VERSION ""

NS_ :

BS_:

BU_: IZZE_Brake_IR_4D3

BO_ 1239 IZZE_Brake_IR_4D3_Status: 8 IZZE_Brake_IR_4D3
 SG_ IZZE_Brake_IR_4D3_Internal_Temp : 7|16@0+ (0.1,-100) [0|65535] "C" Vector__XXX

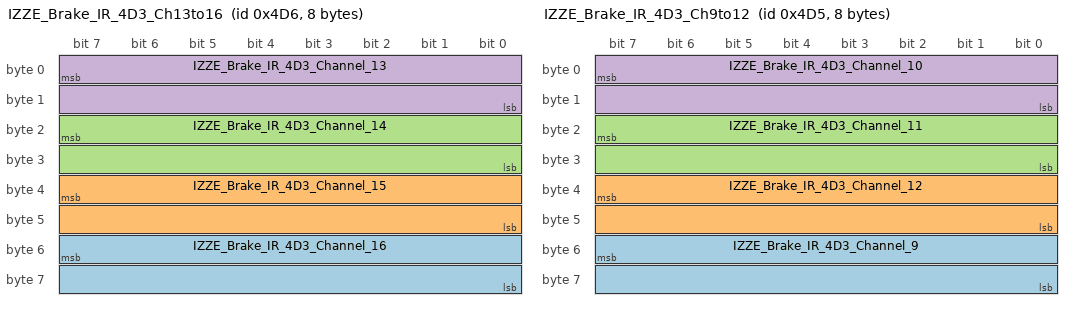
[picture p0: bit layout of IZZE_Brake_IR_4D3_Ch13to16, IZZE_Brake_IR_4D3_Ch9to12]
BO_ 1238 IZZE_Brake_IR_4D3_Ch13to16: 8 IZZE_Brake_IR_4D3
 SG_ IZZE_Brake_IR_4D3_Channel_16 : 55|16@0+ (0.1,-100) [0|65535] "C" Vector__XXX
 SG_ IZZE_Brake_IR_4D3_Channel_15 : 39|16@0+ (0.1,-100) [0|65535] "C" Vector__XXX
 SG_ IZZE_Brake_IR_4D3_Channel_14 : 23|16@0+ (0.1,-100) [0|65535] "C" Vector__XXX
 SG_ IZZE_Brake_IR_4D3_Channel_13 : 7|16@0+ (0.1,-100) [0|65535] "C" Vector__XXX

BO_ 1237 IZZE_Brake_IR_4D3_Ch9to12: 8 IZZE_Brake_IR_4D3
 SG_ IZZE_Brake_IR_4D3_Channel_9 : 55|16@0+ (0.1,-100) [0|65535] "C" Vector__XXX
 SG_ IZZE_Brake_IR_4D3_Channel_12 : 39|16@0+ (0.1,-100) [0|65535] "C" Vector__XXX
 SG_ IZZE_Brake_IR_4D3_Channel_11 : 23|16@0+ (0.1,-100) [0|65535] "C" Vector__XXX
 SG_ IZZE_Brake_IR_4D3_Channel_10 : 7|16@0+ (0.1,-100) [0|65535] "C" Vector__XXX

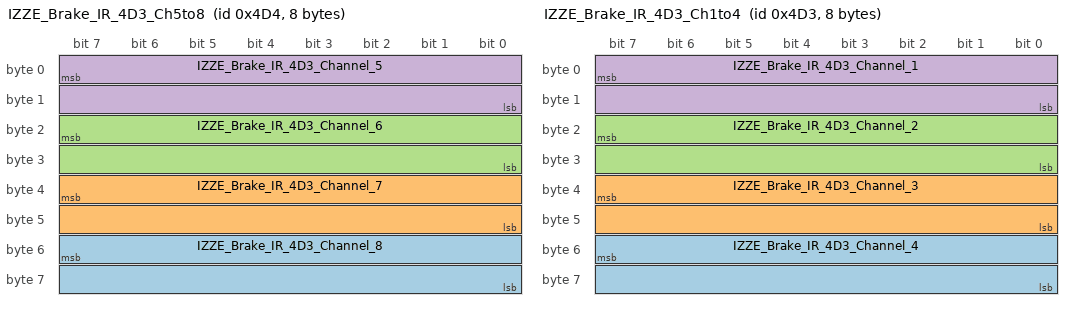
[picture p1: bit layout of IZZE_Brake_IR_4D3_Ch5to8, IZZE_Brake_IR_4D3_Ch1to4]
BO_ 1236 IZZE_Brake_IR_4D3_Ch5to8: 8 IZZE_Brake_IR_4D3
 SG_ IZZE_Brake_IR_4D3_Channel_8 : 55|16@0+ (0.1,-100) [0|65535] "C" Vector__XXX
 SG_ IZZE_Brake_IR_4D3_Channel_7 : 39|16@0+ (0.1,-100) [0|65535] "C" Vector__XXX
 SG_ IZZE_Brake_IR_4D3_Channel_6 : 23|16@0+ (0.1,-100) [0|65535] "C" Vector__XXX
 SG_ IZZE_Brake_IR_4D3_Channel_5 : 7|16@0+ (0.1,-100) [0|65535] "C" Vector__XXX

BO_ 1235 IZZE_Brake_IR_4D3_Ch1to4: 8 IZZE_Brake_IR_4D3
 SG_ IZZE_Brake_IR_4D3_Channel_4 : 55|16@0+ (0.1,-100) [0|65535] "C" Vector__XXX
 SG_ IZZE_Brake_IR_4D3_Channel_3 : 39|16@0+ (0.1,-100) [0|65535] "C" Vector__XXX
 SG_ IZZE_Brake_IR_4D3_Channel_2 : 23|16@0+ (0.1,-100) [0|65535] "C" Vector__XXX
 SG_ IZZE_Brake_IR_4D3_Channel_1 : 7|16@0+ (0.1,-100) [0|65535] "C" Vector__XXX

CM_ BO_ 1239 "Brake IR channels 13-16";
CM_ BO_ 1238 "Brake IR channels 13-16";
CM_ BO_ 1237 "Brake IR channels 9-12";
CM_ BO_ 1236 "Brake IR channels 5-8";
CM_ BO_ 1235 "Brake IR channels 1-4";
BA_DEF_  "BusType" STRING ;
BA_DEF_DEF_  "BusType" "";
BA_ "BusType" "CAN";
